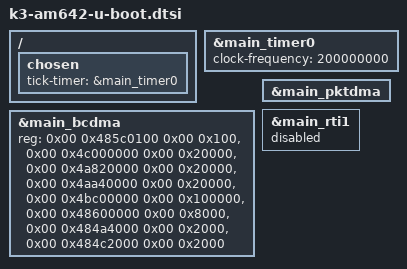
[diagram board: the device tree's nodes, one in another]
// SPDX-License-Identifier: GPL-2.0
/*
 * Common AM642 U-Boot dts file
 * Copyright (C) 2020-2021 Texas Instruments Incorporated - https://www.ti.com/
 */

/ {
	chosen {
		tick-timer = &main_timer0;
	};
};

&main_timer0 {
	clock-frequency = <200000000>;
};

&main_bcdma {
	reg = <0x00 0x485c0100 0x00 0x100>,
	      <0x00 0x4c000000 0x00 0x20000>,
	      <0x00 0x4a820000 0x00 0x20000>,
	      <0x00 0x4aa40000 0x00 0x20000>,
	      <0x00 0x4bc00000 0x00 0x100000>,
	      <0x00 0x48600000 0x00 0x8000>,
	      <0x00 0x484a4000 0x00 0x2000>,
	      <0x00 0x484c2000 0x00 0x2000>;
	reg-names = "gcfg", "bchanrt", "rchanrt", "tchanrt", "ringrt",
		    "cfg", "tchan", "rchan";
	bootph-all;
};

&main_pktdma {
	bootph-all;
};

&main_rti1 {
	status = "disabled";
};
